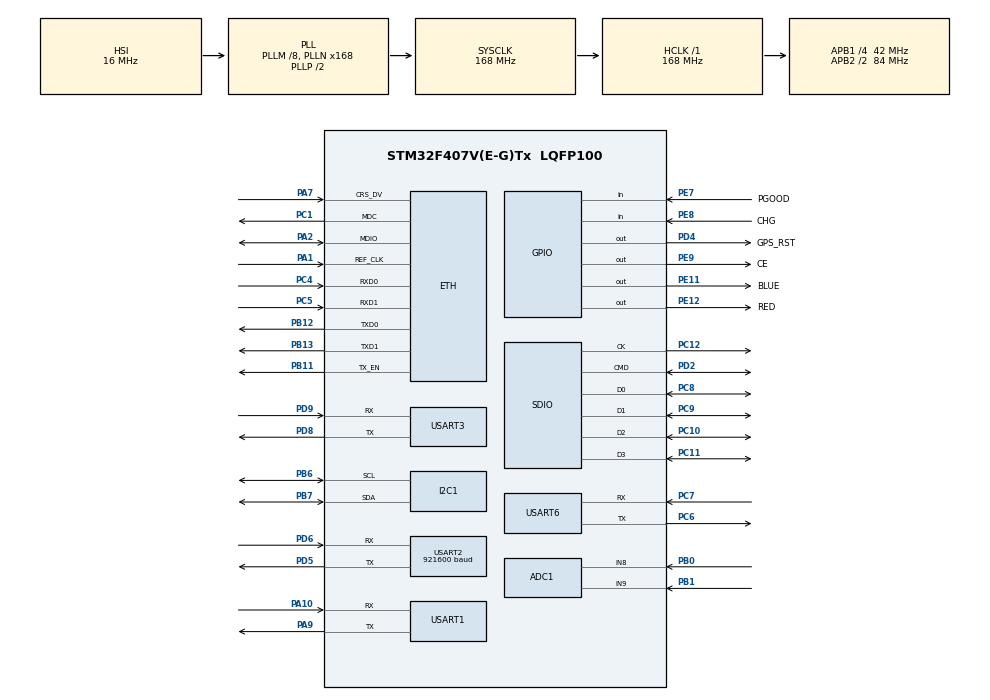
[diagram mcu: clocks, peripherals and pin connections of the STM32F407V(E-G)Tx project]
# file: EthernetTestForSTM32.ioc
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Mcu.Family=STM32F4
Dma.SDIO_TX.1.MemInc=DMA_MINC_ENABLE
PH0-OSC_IN.Signal=RCC_OSC_IN
RCC.CortexFreq_Value=168000000
FATFS._USE_LFN=3
VP_FATFS_VS_SDIO.Mode=SDIO
ADC1.Channel-17\#ChannelRegularConversion=ADC_CHANNEL_8
PE11.GPIO_Label=BLUE
PC10.Signal=SDIO_D2
PC12.Signal=SDIO_CK
ADC1.Rank-17\#ChannelRegularConversion=1
PE11.PinState=GPIO_PIN_SET
PC5.Mode=RMII
PB11.Signal=ETH_TX_EN
PB13.Signal=ETH_TXD1
Dma.SDIO_TX.1.PeriphBurst=DMA_PBURST_INC4
PD9.Mode=Asynchronous
RCC.SYSCLKSource=RCC_SYSCLKSOURCE_PLLCLK
ProjectManager.StackSize=0x2000
Dma.SDIO_RX.0.Direction=DMA_PERIPH_TO_MEMORY
VP_FREERTOS_VS_CMSIS_V2.Mode=CMSIS_V2
LWIP.NETMASK_ADDRESS=255.255.255.000
Dma.SDIO_TX.1.Instance=DMA2_Stream6
Dma.SDIO_TX.1.PeriphInc=DMA_PINC_DISABLE
Dma.SDIO_TX.1.PeriphDataAlignment=DMA_PDATAALIGN_WORD
RCC.HCLKFreq_Value=168000000
PD4.Signal=GPIO_Output
RCC.APB2TimFreq_Value=168000000
PB6.Signal=I2C1_SCL
PC7.Signal=USART6_RX
PB6.Mode=I2C
PD8.Signal=USART3_TX
Dma.SDIO_TX.1.FIFOMode=DMA_FIFOMODE_ENABLE
RCC.AHBFreq_Value=168000000
PH0-OSC_IN.Mode=HSE-External-Oscillator
PD5.Mode=Asynchronous
NVIC.ETH_IRQn=true\:5\:0\:false\:false\:true\:true\:false\:true
RCC.HSE_VALUE=8000000
NVIC.TIM8_TRG_COM_TIM14_IRQn=true\:0\:0\:false\:false\:true\:false\:false\:true
PB3.Mode=Trace_Asynchronous_SW
ADC1.ScanConvMode=ENABLE
Dma.SDIO_TX.1.MemBurst=DMA_MBURST_INC4
PE9.Signal=GPIO_Output
PA14.Mode=Trace_Asynchronous_SW
SH.ADCx_IN8.0=ADC1_IN8,IN8
PC9.Mode=SD_4_bits_Wide_bus
PB7.Signal=I2C1_SDA
Dma.SDIO_TX.1.Direction=DMA_MEMORY_TO_PERIPH
VP_SYS_VS_tim14.Mode=TIM14
Dma.SDIO_RX.0.MemDataAlignment=DMA_MDATAALIGN_WORD
PH1-OSC_OUT.Mode=HSE-External-Oscillator
Mcu.Package=LQFP100
PB1.Signal=ADCx_IN9
PB12.Mode=RMII
NVIC.TimeBase=TIM8_TRG_COM_TIM14_IRQn
USART2.VirtualMode=VM_ASYNC
USART6.VirtualMode=VM_ASYNC
NVIC.TimeBaseIP=TIM14
PA10.Signal=USART1_RX
PE12.GPIO_Label=RED
ADC1.SamplingTime-17\#ChannelRegularConversion=ADC_SAMPLETIME_480CYCLES
PC11.Mode=SD_4_bits_Wide_bus
SH.ADCx_IN9.0=ADC1_IN9,IN9
Dma.SDIO_TX.1.FIFOThreshold=DMA_FIFO_THRESHOLD_FULL
Dma.SDIO_TX.1.Priority=DMA_PRIORITY_LOW
RCC.APB2CLKDivider=RCC_HCLK_DIV2
Dma.Request1=SDIO_TX
RCC.APB1TimFreq_Value=84000000
PC5.Signal=ETH_RXD1
Dma.SDIO_RX.0.MemBurst=DMA_MBURST_INC4
PB13.Mode=RMII
Dma.SDIO_RX.0.Instance=DMA2_Stream3
PE7.Signal=GPIO_Input
PD6.Signal=USART2_RX
Dma.Request0=SDIO_RX
LWIP.PBUF_POOL_SIZE=32
PC4.Mode=RMII
Dma.SDIO_RX.0.FIFOMode=DMA_FIFOMODE_ENABLE
LWIP.IP_ADDRESS=192.168.111.020
Dma.SDIO_RX.0.Mode=DMA_PFCTRL
Dma.SDIO_RX.0.Priority=DMA_PRIORITY_LOW
FREERTOS.Tasks01=EthernetTask,24,2048,StartEthernetTask,Default,NULL,Dynamic,NULL,NULL
PA7.Mode=RMII
ETH.PHY_User_Name=LAN8720
PA10.Mode=Asynchronous
PE11.GPIO_Speed=GPIO_SPEED_FREQ_LOW
PC11.Signal=SDIO_D3
ADC1.Rank-18\#ChannelRegularConversion=2
PC8.Signal=SDIO_D0
Dma.SDIO_RX.0.PeriphInc=DMA_PINC_DISABLE
PC4.Signal=ETH_RXD0
PC6.Signal=USART6_TX
PC10.Mode=SD_4_bits_Wide_bus
ADC1.DiscontinuousConvMode=ENABLE
ETH.MACAddr=00\:80\:E1\:00\:00\:0D
PD9.Signal=USART3_RX
PD5.Signal=USART2_TX
LWIP.LWIP_DHCP=0
RCC.APB1CLKDivider=RCC_HCLK_DIV4
PD6.Mode=Asynchronous
ETH.PhyAddress=0
NVIC.USART2_IRQn=true\:5\:0\:false\:false\:true\:true\:true\:true
USART2.BaudRate=921600
NVIC.SDIO_IRQn=true\:5\:0\:false\:false\:true\:true\:true\:true
VP_LWIP_VS_Enabled.Mode=Enabled
LWIP.GATEWAY_ADDRESS=192.168.111.001
PA13.Signal=SYS_JTMS-SWDIO
PD4.PinState=GPIO_PIN_SET
PA9.Mode=Asynchronous
Dma.SDIO_TX.1.MemDataAlignment=DMA_MDATAALIGN_WORD
Dma.SDIO_RX.0.MemInc=DMA_MINC_ENABLE
ETH.PHY_Name_RMII=userPHY
PB11.Mode=RMII
Dma.SDIO_RX.0.FIFOThreshold=DMA_FIFO_THRESHOLD_FULL
ProjectManager.TargetToolchain=STM32CubeIDE
PC6.Mode=Asynchronous
ADC1.Channel-18\#ChannelRegularConversion=ADC_CHANNEL_9
PE8.GPIO_Label=CHG
PA9.Signal=USART1_TX
NVIC.DMA2_Stream3_IRQn=true\:6\:0\:true\:false\:true\:true\:false\:true
NVIC.DMA2_Stream6_IRQn=true\:6\:0\:true\:false\:true\:true\:false\:true
PE11.Signal=GPIO_Output
RCC.LSE_VALUE=32768
PE9.GPIO_Label=CE
PD8.Mode=Asynchronous
PA1.Signal=ETH_REF_CLK
Dma.SDIO_RX.0.PeriphDataAlignment=DMA_PDATAALIGN_WORD
PD2.Mode=SD_4_bits_Wide_bus
PC12.Mode=SD_4_bits_Wide_bus
board=custom
RCC.VCOOutputFreq_Value=336000000
ETH.PHY_SR=31
LWIP.LWIP_TFTP=1
RCC.APB2Freq_Value=84000000
PA1.Mode=RMII
PE8.Signal=GPIO_Input
PD4.GPIO_Label=GPS_RST
PH1-OSC_OUT.Signal=RCC_OSC_OUT
Dma.SDIO_TX.1.Mode=DMA_PFCTRL
ADC1.NbrOfConversion=2
PA13.Mode=Trace_Asynchronous_SW
Mcu.Name=STM32F407V(E-G)Tx
PE7.GPIO_Label=PGOOD
PE12.Signal=GPIO_Output
PA2.Signal=ETH_MDIO
PE12.PinState=GPIO_PIN_SET
PC8.Mode=SD_4_bits_Wide_bus
RCC.48MHZClocksFreq_Value=48000000
PB3.Signal=SYS_JTDO-SWO
RCC.SYSCLKFreq_VALUE=168000000
ETH.MediaInterface=ETH_MEDIA_INTERFACE_RMII
ADC1.master=1
USART3.VirtualMode=VM_ASYNC
USART1.VirtualMode=VM_ASYNC
PB7.Mode=I2C
PA14.Signal=SYS_JTCK-SWCLK
ProjectManager.HeapSize=0x3000
LWIP.Version=v2.1.2_Cube
RCC.HSI_VALUE=16000000
RCC.PLLQ=7
NVIC.PriorityGroup=NVIC_PRIORITYGROUP_4
ADC1.NbrOfConversionFlag=1
RCC.PLLM=8
RCC.PLLN=168
Dma.SDIO_RX.0.PeriphBurst=DMA_PBURST_INC4
PA2.Mode=RMII
PC9.Signal=SDIO_D1
PC7.Mode=Asynchronous
PD2.Signal=SDIO_CMD
RCC.APB1Freq_Value=42000000
VP_CRC_VS_CRC.Mode=CRC_Activate
PB0.Signal=ADCx_IN8
ADC1.SamplingTime-18\#ChannelRegularConversion=ADC_SAMPLETIME_480CYCLES
PC1.Signal=ETH_MDC
PB12.Signal=ETH_TXD0
PC1.Mode=RMII
PA7.Signal=ETH_CRS_DV

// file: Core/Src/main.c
/* USER CODE BEGIN Header */
/**
  ******************************************************************************
  * @file           : main.c
  * @brief          : Main program body
  ******************************************************************************
  * @attention
  *
  * <h2><center>&copy; Copyright (c) 2021 STMicroelectronics.
  * All rights reserved.</center></h2>
  *
  * This software component is licensed by ST under Ultimate Liberty license
  * SLA0044, the "License"; You may not use this file except in compliance with
  * the License. You may obtain a copy of the License at:
  *                             www.st.com/SLA0044
  *
  ******************************************************************************
  */
/* USER CODE END Header */
#include "main.h"
#include "cmsis_os.h"
#include "adc.h"
#include "crc.h"
#include "dma.h"
#include "fatfs.h"
#include "i2c.h"
#include "lwip.h"
#include "sdio.h"
#include "usart.h"
#include "gpio.h"

void SystemClock_Config(void);
void MX_FREERTOS_Init(void);

int main(void)
{

  /* MCU Configuration--------------------------------------------------------*/

  /* Reset of all peripherals, Initializes the Flash interface and the Systick. */
  HAL_Init();

  /* Configure the system clock */
  SystemClock_Config();

  /* Initialize all configured peripherals */
  MX_GPIO_Init();
  MX_DMA_Init();
  MX_ADC1_Init();
  MX_I2C1_Init();
  MX_USART1_UART_Init();
  MX_USART2_UART_Init();
  MX_USART3_UART_Init();
  MX_USART6_UART_Init();
  MX_CRC_Init();
  MX_SDIO_SD_Init();
  MX_FATFS_Init();

  /* Init scheduler */
  osKernelInitialize();  /* Call init function for freertos objects (in freertos.c) */
  MX_FREERTOS_Init();
  /* Start scheduler */
  osKernelStart();

  /* We should never get here as control is now taken by the scheduler */
  /* Infinite loop */
  while (1)
  {

  }
}

void SystemClock_Config(void)
{
  RCC_OscInitTypeDef RCC_OscInitStruct = {0};
  RCC_ClkInitTypeDef RCC_ClkInitStruct = {0};

  /** Configure the main internal regulator output voltage
  */
  __HAL_RCC_PWR_CLK_ENABLE();
  __HAL_PWR_VOLTAGESCALING_CONFIG(PWR_REGULATOR_VOLTAGE_SCALE1);
  /** Initializes the RCC Oscillators according to the specified parameters
  * in the RCC_OscInitTypeDef structure.
  */
  RCC_OscInitStruct.OscillatorType = RCC_OSCILLATORTYPE_HSI;
  RCC_OscInitStruct.HSIState = RCC_HSI_ON;
  RCC_OscInitStruct.HSICalibrationValue = RCC_HSICALIBRATION_DEFAULT;
  RCC_OscInitStruct.PLL.PLLState = RCC_PLL_ON;
  RCC_OscInitStruct.PLL.PLLSource = RCC_PLLSOURCE_HSI;
  RCC_OscInitStruct.PLL.PLLM = 8;
  RCC_OscInitStruct.PLL.PLLN = 168;
  RCC_OscInitStruct.PLL.PLLP = RCC_PLLP_DIV2;
  RCC_OscInitStruct.PLL.PLLQ = 7;
  if (HAL_RCC_OscConfig(&RCC_OscInitStruct) != HAL_OK)
  {
    Error_Handler();
  }
  /** Initializes the CPU, AHB and APB buses clocks
  */
  RCC_ClkInitStruct.ClockType = RCC_CLOCKTYPE_HCLK|RCC_CLOCKTYPE_SYSCLK
                              |RCC_CLOCKTYPE_PCLK1|RCC_CLOCKTYPE_PCLK2;
  RCC_ClkInitStruct.SYSCLKSource = RCC_SYSCLKSOURCE_PLLCLK;
  RCC_ClkInitStruct.AHBCLKDivider = RCC_SYSCLK_DIV1;
  RCC_ClkInitStruct.APB1CLKDivider = RCC_HCLK_DIV4;
  RCC_ClkInitStruct.APB2CLKDivider = RCC_HCLK_DIV2;

  if (HAL_RCC_ClockConfig(&RCC_ClkInitStruct, FLASH_LATENCY_5) != HAL_OK)
  {
    Error_Handler();
  }
}

 /**
  * @brief  Period elapsed callback in non blocking mode
  * @note   This function is called  when TIM14 interrupt took place, inside
  * HAL_TIM_IRQHandler(). It makes a direct call to HAL_IncTick() to increment
  * a global variable "uwTick" used as application time base.
  * @param  htim : TIM handle
  * @retval None
  */
void HAL_TIM_PeriodElapsedCallback(TIM_HandleTypeDef *htim)
{
  if (htim->Instance == TIM14) {
    HAL_IncTick();
  }
}

void Error_Handler(void)
{
  __disable_irq();
  while (1)
  {
  }
}

/************************ (C) COPYRIGHT STMicroelectronics *****END OF FILE****/

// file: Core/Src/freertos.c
/* USER CODE BEGIN Header */
/**
  ******************************************************************************
  * File Name          : freertos.c
  * Description        : Code for freertos applications
  ******************************************************************************
  * @attention
  *
  * <h2><center>&copy; Copyright (c) 2021 STMicroelectronics.
  * All rights reserved.</center></h2>
  *
  * This software component is licensed by ST under Ultimate Liberty license
  * SLA0044, the "License"; You may not use this file except in compliance with
  * the License. You may obtain a copy of the License at:
  *                             www.st.com/SLA0044
  *
  ******************************************************************************
  */
/* USER CODE END Header */

#include "FreeRTOS.h"
#include "task.h"
#include "main.h"
#include "cmsis_os.h"

/* Definitions for EthernetTask */
osThreadId_t EthernetTaskHandle;
const osThreadAttr_t EthernetTask_attributes = {
  .name = "EthernetTask",
  .priority = (osPriority_t) osPriorityNormal,
  .stack_size = 2048 * 4
};

/* USER CODE BEGIN FunctionPrototypes */
extern void tcpecho_init(void);
extern void udpecho_init(void);
/* USER CODE END FunctionPrototypes */

void StartEthernetTask(void *argument);

extern void MX_LWIP_Init(void);
void MX_FREERTOS_Init(void); /* (MISRA C 2004 rule 8.1) */

void MX_FREERTOS_Init(void) {

  /* Create the thread(s) */
  /* creation of EthernetTask */
  EthernetTaskHandle = osThreadNew(StartEthernetTask, NULL, &EthernetTask_attributes);

}

void StartEthernetTask(void *argument)
{
  /* init code for LWIP */
  MX_LWIP_Init();
  /* USER CODE BEGIN StartEthernetTask */
  udpecho_init();
  tcpecho_init();

  /* Infinite loop */
  for(;;)
  {
    osDelay(1);
    osThreadTerminate(NULL);
  }
  /* USER CODE END StartEthernetTask */
}

/************************ (C) COPYRIGHT STMicroelectronics *****END OF FILE****/
